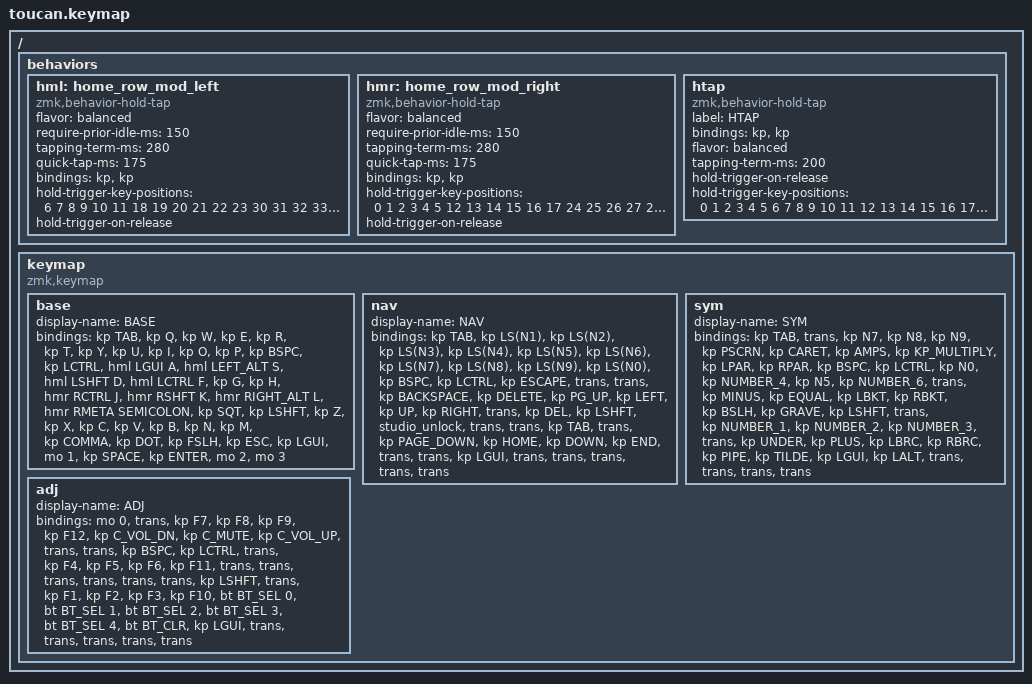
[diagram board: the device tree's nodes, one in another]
#include <behaviors.dtsi>
#include <dt-bindings/zmk/bt.h>
#include <dt-bindings/zmk/keys.h>

#define BASE 0
#define NAV  1
#define SYM  2
#define ADJ  3

/ {
    behaviors {
        hml: home_row_mod_left {
            compatible = "zmk,behavior-hold-tap";
            #binding-cells = <2>;
            flavor = "balanced";
            require-prior-idle-ms = <150>;
            tapping-term-ms = <280>;
            quick-tap-ms = <175>;
            bindings = <&kp>, <&kp>;

            hold-trigger-key-positions = <6 7 8 9 10 11 18 19 20 21 22 23 30 31 32 33 34 35 39 40 41>; // List of keys on the right side of the keyboard
            hold-trigger-on-release;
        };

        hmr: home_row_mod_right {
            compatible = "zmk,behavior-hold-tap";
            #binding-cells = <2>;
            flavor = "balanced";
            require-prior-idle-ms = <150>;
            tapping-term-ms = <280>;
            quick-tap-ms = <175>;
            bindings = <&kp>, <&kp>;

            hold-trigger-key-positions = <0 1 2 3 4 5 12 13 14 15 16 17 24 25 26 27 28 29 36 37 38>; // List of keys on the left side of the keyboard
            hold-trigger-on-release;
        };

        htap: htap {
            compatible = "zmk,behavior-hold-tap";
            label = "HTAP";
            bindings = <&kp>, <&kp>;

            #binding-cells = <2>;
            flavor = "balanced";
            tapping-term-ms = <200>;
            hold-trigger-on-release;
            hold-trigger-key-positions = <0 1 2 3 4 5 6 7 8 9 10 11 12 13 14 15 16 17 18 19 20 21 22 23 24 25 26 27 28 29 30 31 32 33 34 35 36 37 38 39 40 41>;
        };
    };

    keymap {
        compatible = "zmk,keymap";

        base {
            display-name = "BASE";
            bindings = <
&kp TAB  &kp Q  &kp W  &kp E  &kp R  &kp T  &kp Y  &kp U  &kp I  &kp O  &kp P  &kp BSPC  &kp LCTRL  &hml LGUI A  &hml LEFT_ALT S  &hml LSHFT D  &hml LCTRL F  &kp G  &kp H  &hmr RCTRL J  &hmr RSHFT K  &hmr RIGHT_ALT L  &hmr RMETA SEMICOLON  &kp SQT  &kp LSHFT  &kp Z  &kp X  &kp C  &kp V  &kp B  &kp N  &kp M  &kp COMMA  &kp DOT  &kp FSLH  &kp ESC  &kp LGUI  &mo 1  &kp SPACE  &kp ENTER  &mo 2  &mo 3
            >;
        };

        nav {
            display-name = "NAV";
            bindings = <
&kp TAB  &kp LS(N1)  &kp LS(N2)  &kp LS(N3)  &kp LS(N4)  &kp LS(N5)  &kp LS(N6)  &kp LS(N7)  &kp LS(N8)  &kp LS(N9)  &kp LS(N0)  &kp BSPC  &kp LCTRL  &kp ESCAPE  &trans  &trans  &kp BACKSPACE  &kp DELETE  &kp PG_UP  &kp LEFT  &kp UP  &kp RIGHT  &trans  &kp DEL  &kp LSHFT  &studio_unlock  &trans  &trans  &kp TAB  &trans  &kp PAGE_DOWN  &kp HOME  &kp DOWN  &kp END  &trans  &trans  &kp LGUI  &trans  &trans  &trans  &trans  &trans
            >;
        };

        sym {
            display-name = "SYM";
            bindings = <
&kp TAB  &trans  &kp N7  &kp N8  &kp N9  &kp PSCRN  &kp CARET  &kp AMPS  &kp KP_MULTIPLY  &kp LPAR  &kp RPAR  &kp BSPC  &kp LCTRL  &kp N0  &kp NUMBER_4  &kp N5  &kp NUMBER_6  &trans  &kp MINUS  &kp EQUAL  &kp LBKT  &kp RBKT  &kp BSLH  &kp GRAVE  &kp LSHFT  &trans  &kp NUMBER_1  &kp NUMBER_2  &kp NUMBER_3  &trans  &kp UNDER  &kp PLUS  &kp LBRC  &kp RBRC  &kp PIPE  &kp TILDE  &kp LGUI  &kp LALT  &trans  &trans  &trans  &trans
            >;
        };

        adj {
            display-name = "ADJ";
            bindings = <
&mo 0  &trans  &kp F7  &kp F8  &kp F9  &kp F12  &kp C_VOL_DN  &kp C_MUTE  &kp C_VOL_UP  &trans  &trans  &kp BSPC  &kp LCTRL  &trans  &kp F4  &kp F5  &kp F6  &kp F11  &trans  &trans  &trans  &trans  &trans  &trans  &kp LSHFT  &trans  &kp F1  &kp F2  &kp F3  &kp F10  &bt BT_SEL 0  &bt BT_SEL 1  &bt BT_SEL 2  &bt BT_SEL 3  &bt BT_SEL 4  &bt BT_CLR  &kp LGUI  &trans  &trans  &trans  &trans  &trans
            >;
        };
    };
};
